# YC3122 register map
Series: ARMCM0; File version: 1.0
CPU: CM0 r1p0, little endian, no MPU, no FPU, 8 interrupt priority bits
Registers are 32-bit, read-write, reset 0x0 unless marked. A register's access mark holds for its fields unless they carry their own. Offsets are from the block's base; [hi:lo] are bit positions; {n}, {i} and the like mark numbered series.

## MGPIO — 8 GPIO
Base 0x000F8700
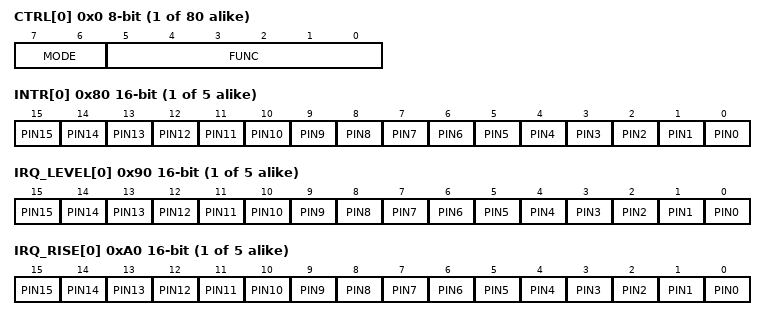
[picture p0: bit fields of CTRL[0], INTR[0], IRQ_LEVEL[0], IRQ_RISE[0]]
{0x0+i} CTRL[{i}] (i=0..79) 8-bit
  [7:6] MODE — GPIO mode
  [5:0] FUNC — GPIO function
{0x80+2i} INTR[{i}] (i=0..4) 16-bit
  [n] PIN{n} (n=0..15)
{0x90+2i} IRQ_LEVEL[{i}] (i=0..4) 16-bit
  [n] PIN{n} (n=0..15)
{0xA0+2i} IRQ_RISE[{i}] (i=0..4) 16-bit
  [n] PIN{n} (n=0..15)
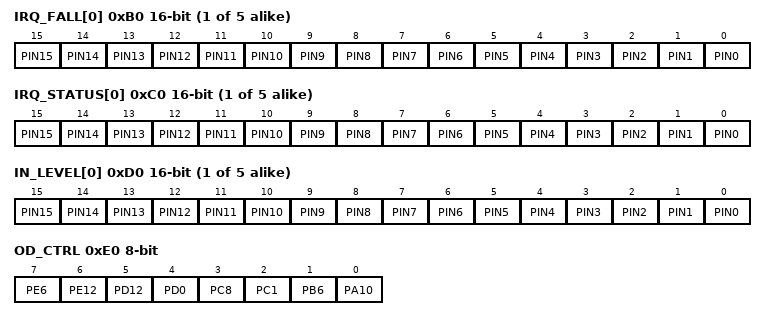
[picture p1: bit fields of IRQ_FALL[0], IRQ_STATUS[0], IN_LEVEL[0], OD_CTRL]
{0xB0+2i} IRQ_FALL[{i}] (i=0..4) 16-bit
  [n] PIN{n} (n=0..15)
{0xC0+2i} IRQ_STATUS[{i}] (i=0..4) 16-bit
  [n] PIN{n} (n=0..15)
0xCF IRQ_NUM 8-bit — GPIO_IRQ_INDEX register
  [7:0] INDEX ro — GPIO_IRQ_INDEX
{0xD0+2i} IN_LEVEL[{i}] (i=0..4) 16-bit
  [n] PIN{n} (n=0..15)
0xE0 OD_CTRL 8-bit — GPIO_OD register
  [7] PE6 — GPIO_OD
  [6] PE12 — GPIO_OD
  [5] PD12 — GPIO_OD
  [4] PD0 — GPIO_OD
  [3] PC8 — GPIO_OD
  [2] PC1 — GPIO_OD
  [1] PB6 — GPIO_OD
  [0] PA10 — GPIO_OD

## MDMA — 32 DMA
Base 0x000F8800
Same registers: MDMA_QSPI 0x000F8800 (alternate view of MDMA), MDMA_SPI0 0x000F8900, MDMA_SPI1 0x000F8A00, MDMA_UART0 0x000F8B00, MDMA_UART1 0x000F8C00, MDMA_UART2 0x000F8D00, MDMA_UART3 0x000F8E00, MDMA_7811 0x000F8F00, MDMA_MEMCP 0x000F9000, MDMA_IIC0 0x000F9100, MDMA_IIC1 0x000F9200
0x00 SRC_ADDR — DMA_SRC_ADDR register
  [31:0] VAL wo — source address
0x04 DEST_ADDR — DMA_DEST_ADDR register
  [31:0] VAL wo — dest address
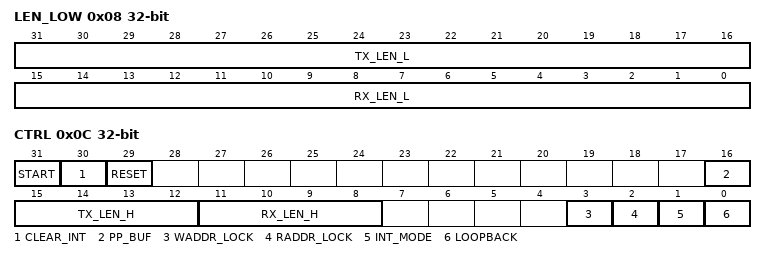
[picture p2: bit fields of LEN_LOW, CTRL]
0x08 LEN_LOW — DMA_LEN_LOW register
  [31:16] TX_LEN_L — buff len
  [15:0] RX_LEN_L — buff len
0x0C CTRL — DMA control register
  [31] START — enable DMA
  [30] CLEAR_INT — clear DMA int
  [29] RESET — init write 0,write 1
  [16] PP_BUF — flag slave/dcmi
  [15:12] TX_LEN_H — tx len
  [11:8] RX_LEN_H — rx len
  [3] WADDR_LOCK — lock write addr
  [2] RADDR_LOCK — lock read addr
  [1] INT_MODE — enable interrupt
  [0] LOOPBACK — loop back mode
0x10 STATUS — DMA status
  [0] DONE ro
0x14 RPTR — Sends the current address of the BUF read pointer
  [31:0] VAL ro
0x18 WPRT — received the current address of the BUF read pointer
  [31:0] VAL ro — receiced the current address of the BUF read pointer

## MSPI
Base 0x000F891C
Same registers: MSPI0 0x000F891C (alternate view of MSPI), MSPI1 0x000F8A1C
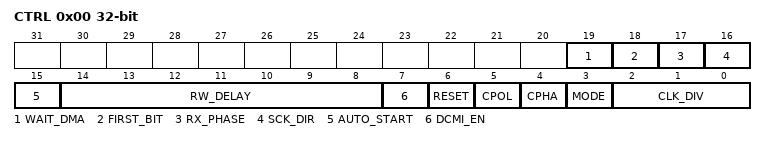
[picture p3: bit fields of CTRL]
0x00 CTRL
  [19] WAIT_DMA — 0: ignore dma status. 1: 等待dma 完全写入ram ,再开始接收下1 by te
  [18] FIRST_BIT — 1: 先发送lsb. 0:先发送MSB
  [17] RX_PHASE — 0: normal receive sample point. 1: receive sample point dela y one clock of ahb_bus
  [16] SCK_DIR — ncs 与 sck 输入输出选择 0: 输出(master mode). 1: 输入(slave mode)
  [15] AUTO_START — 1: spi dma可以被dcmi多行中断自动启 动
  [14:8] RW_DELAY — 反向间隔（value*16个clock）
  [7] DCMI_EN — 0: 8-bit spi mode. 1: 8-bit byte y extended to. 16-bit rgb565
  [6] RESET — spi_reset
  [5] CPOL — CPOL （空闲状态时钟电平） 1: High. 0: Low
  [4] CPHA — CPHA 1: 偶数边沿采样 0: 奇数边沿 采样
  [3] MODE — 0: Master Mode 1：Slave. Mode
  [2:0] CLK_DIV — SPICLK 分频系数 (1<<CTRL[2:0 ])

## MUART
Base 0x000F8B1C
Same registers: MUART0 0x000F8B1C (alternate view of MUART), MUART1 0x000F8C1C, MUART2 0x000F8D1C, MUART3 0x000F8E1C
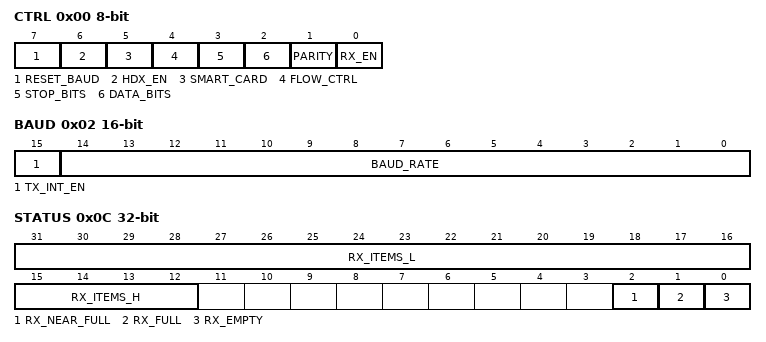
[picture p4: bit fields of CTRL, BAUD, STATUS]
0x00 CTRL 8-bit
  [7] RESET_BAUD — UART重置波特率位 0：无操作 1：必须先配置好波特率，置位1后 波特率才能生效。
  [6] HDX_EN — UART全双工/双工模式控制位 0：全双工 1：半双工
  [5] SMART_CARD — UART 智能卡模式控制位 0：关闭智能卡 1：开启智能卡模式
  [4] FLOW_CTRL — UART 模块流控控制位 0：无流控模式 1：有流控模式
  [3] STOP_BITS — UART 停止位 0：1bit停止位 1：2bit停止位
  [2] DATA_BITS — UART 校验使能位 0：无校验位,仅发送8bit数据 1：有校验位,发送9bit数据。
  [1] PARITY — UART 校验位 0：Parity_Even(偶校验). 1：Parity_Odd(奇校验)
  [0] RX_EN — UART 使能位 0：失能Rx功能 1：使能Rx功能
0x01 RX_INT_LEN 8-bit
  [7:0] VAL — 控制串口接收中断长度，为0不触发中断
0x02 BAUD 16-bit
  [15] TX_INT_EN — 发送中断使能位 0：失能tx中断 1：使能tx 中断
  [14:0] BAUD_RATE — 配置波特率 (波特率=时钟/寄存器的值)
0x04 TIMEOUT_INT 16-bit
  [15:0] VAL — 0：不启用。当收到数据后开始计时，超时未收到下一 个字节则触发中断，接收超时中断时间值（48*value） 。
0x08 RX_DATA 8-bit
  [7:0] VAL ro — 读取UART的数据
0x0C STATUS
  [31:16] RX_ITEMS_L — 当前RX BUF中的数据个数低16位
  [15:12] RX_ITEMS_H — 当前RX BUF中的数据个数高4位
  [2] RX_NEAR_FULL — 0:rx buf 数据未接近满 1:rx bu f 数据接近满
  [1] RX_FULL — 0:rx buf 未满 1:rx buf 满
  [0] RX_EMPTY — 0:rx buf 非空 1:rx buf 为空
